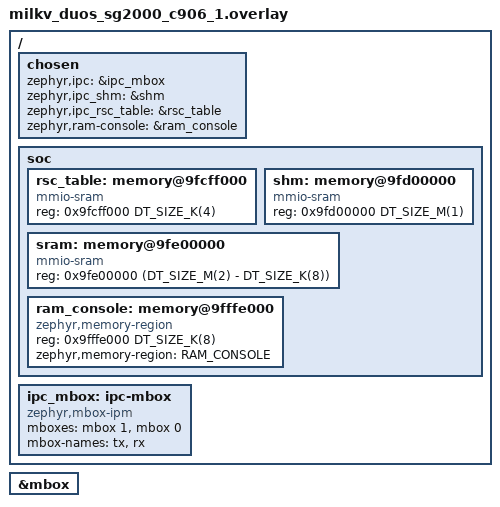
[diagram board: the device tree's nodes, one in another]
/*
 * SPDX-FileCopyrightText: Copyright The Zephyr Project Contributors
 * SPDX-License-Identifier: Apache-2.0
 */

/ {
	chosen {
		zephyr,ipc = &ipc_mbox;
		zephyr,ipc_shm = &shm;
		zephyr,ipc_rsc_table = &rsc_table;
		zephyr,ram-console = &ram_console;
	};

	soc {
		/* Linux c906l_rsc reserved-memory: resource table copy */
		rsc_table: memory@9fcff000 {
			compatible = "mmio-sram";
			reg = <0x9fcff000 DT_SIZE_K(4)>;
		};

		/* Linux c906l_dma shared-dma-pool: vrings and rpmsg buffers */
		shm: memory@9fd00000 {
			compatible = "mmio-sram";
			reg = <0x9fd00000 DT_SIZE_M(1)>;
		};

		sram: memory@9fe00000 {
			compatible = "mmio-sram";
			reg = <0x9fe00000 (DT_SIZE_M(2) - DT_SIZE_K(8))>;
		};

		ram_console: memory@9fffe000 {
			compatible = "zephyr,memory-region";
			reg = <0x9fffe000 DT_SIZE_K(8)>;
			zephyr,memory-region = "RAM_CONSOLE";
		};
	};

	ipc_mbox: ipc-mbox {
		compatible = "zephyr,mbox-ipm";
		/* Linux rx is channel 1, Linux tx is channel 0 */
		mboxes = <&mbox 1>, <&mbox 0>;
		mbox-names = "tx", "rx";
	};
};

&mbox {
	status = "okay";
};
